# STM32G431xx register map
File version: 1.0
Registers are 32-bit, access not given, reset 0x0 unless marked. A register's access mark holds for its fields unless they carry their own. Offsets are from the block's base; [hi:lo] are bit positions; {n}, {i} and the like mark numbered series; 'fields as' and 'values as' point back to an identical list.

## EXTI
Base 0x40010400
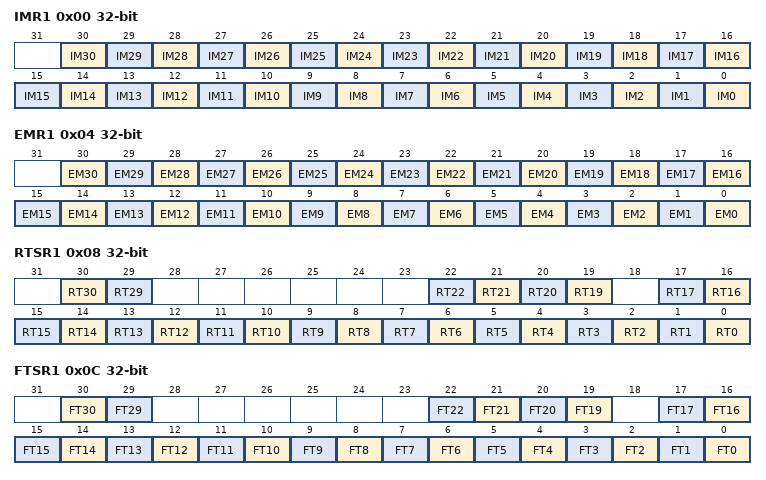
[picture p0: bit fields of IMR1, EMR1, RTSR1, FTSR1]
0x00 IMR1
  [n] IM{n} (n=0..30)
0x04 EMR1
  [n] EM{n} (n=0..30)
0x08 RTSR1
  [30] RT30, [29] RT29, [n] RT{n} (n=19..22), [n] RT{n} (n=0..17)
0x0C FTSR1
  [30] FT30, [29] FT29, [n] FT{n} (n=19..22), [n] FT{n} (n=0..17)
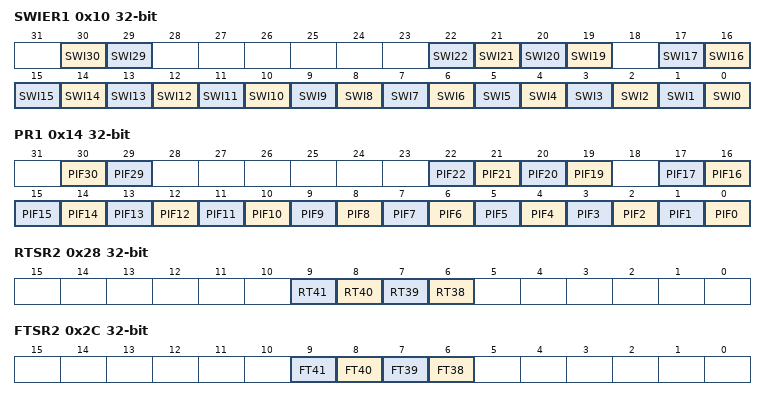
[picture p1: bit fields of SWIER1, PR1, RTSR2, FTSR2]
0x10 SWIER1
  [30] SWI30, [29] SWI29, [n] SWI{n} (n=19..22), [n] SWI{n} (n=0..17)
0x14 PR1
  [30] PIF30, [29] PIF29, [n] PIF{n} (n=19..22), [n] PIF{n} (n=0..17)
0x20 IMR2
  [n-32] IM{n} (n=36..41), [2] IM34, [9:0] IM
0x24 EMR2
  [n-32] EM{n} (n=36..41), [2] EM34, [9:0] EM
0x28 RTSR2
  [n-32] RT{n} (n=38..41)
0x2C FTSR2
  [n-32] FT{n} (n=38..41)
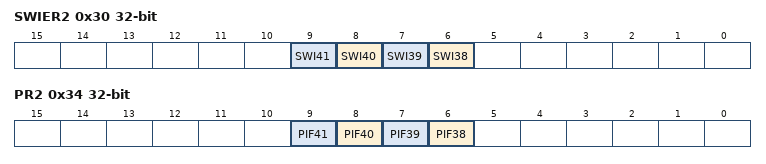
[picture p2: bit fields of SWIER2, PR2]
0x30 SWIER2
  [n-32] SWI{n} (n=38..41)
0x34 PR2
  [n-32] PIF{n} (n=38..41)

## SAI1
Base 0x40015400
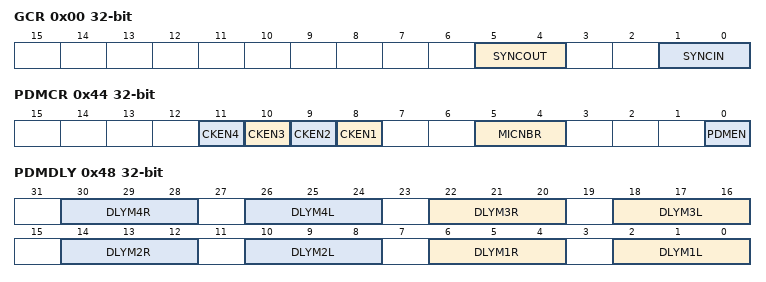
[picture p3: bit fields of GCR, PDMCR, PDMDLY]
0x00 GCR
  [5:4] SYNCOUT, [1:0] SYNCIN
0x04 CR1A
0x08 CR2A
0x10 FRCRA
0x1C SLOTRA
0x24 CR1B
0x28 CR2B
0x2C IMRA
0x30 FRCRB
0x3C SLOTRB
0x40 SRA
0x44 PDMCR
  [n+7] CKEN{n} (n=1..4), [5:4] MICNBR, [0] PDMEN
0x48 PDMDLY
  [8n-2:8n-4] DLYM{n}R (n=1..4), [8n-6:8n-8] DLYM{n}L (n=1..4)
0x4C IMRB
0x58 CLRFRA
0x60 SRB
0x74 DRA
0x78 CLRFRB
0x94 DRB

## DMA1
Base 0x40020000
Same registers: DMA2 0x40020400
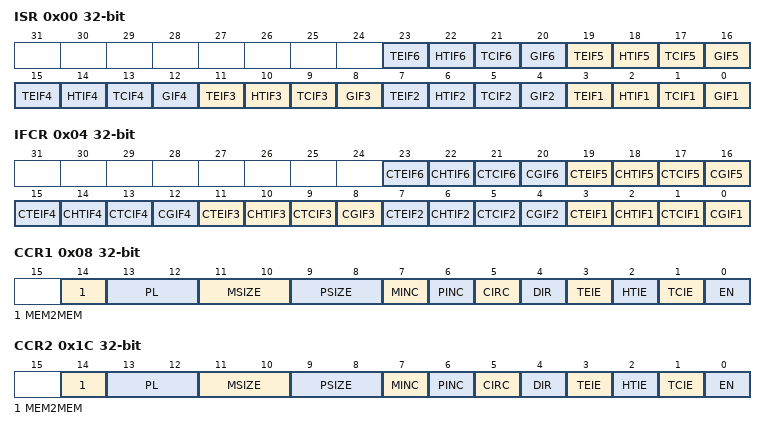
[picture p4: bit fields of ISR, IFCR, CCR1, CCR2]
0x00 ISR
  [4n-1] TEIF{n} (n=1..6), [4n-2] HTIF{n} (n=1..6), [4n-3] TCIF{n} (n=1..6), [4n-4] GIF{n} (n=1..6)
0x04 IFCR
  [4n-1] CTEIF{n} (n=1..6), [4n-2] CHTIF{n} (n=1..6), [4n-3] CTCIF{n} (n=1..6), [4n-4] CGIF{n} (n=1..6)
0x08 CCR1
  [14] MEM2MEM, [13:12] PL, [11:10] MSIZE, [9:8] PSIZE, [7] MINC, [6] PINC, [5] CIRC, [4] DIR, [3] TEIE, [2] HTIE, [1] TCIE, [0] EN
0x0C CNDTR1
  [15:0] NDT
{0x0+0x14*i} CPAR{i} (i=1..6)
  [31:0] PA
0x1C CCR2
  fields as CCR1
{0xC+0x14*i} CMAR{i} (i=1..6)
  [31:0] MA
0x20 CNDTR2
  [15:0] NDT
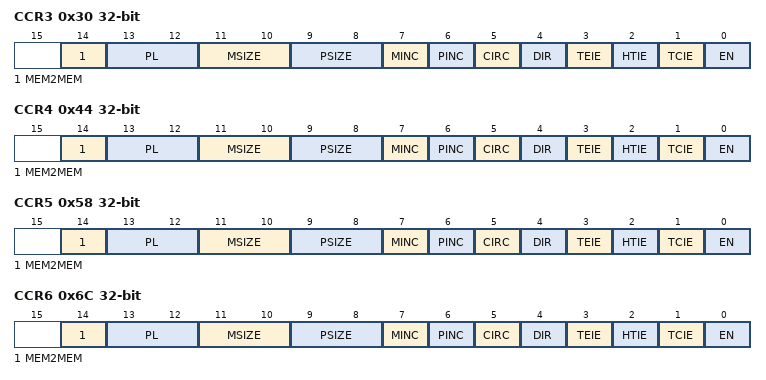
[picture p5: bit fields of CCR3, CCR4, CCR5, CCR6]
0x30 CCR3
  fields as CCR1
0x34 CNDTR3
  [15:0] NDT
0x44 CCR4
  fields as CCR1
0x48 CNDTR4
  [15:0] NDT
0x58 CCR5
  fields as CCR1
0x5C CNDTR5
  [15:0] NDT
0x6C CCR6
  fields as CCR1
0x70 CNDTR6
  [15:0] NDT

## DMAMUX1
Base 0x40020800
0x00 CCR0
0x04 CCR1
0x08 CCR2
0x0C CCR3
0x10 CCR4
0x14 CCR5
{0x8+4i} CCR{i} (i=6..9)
0x30 CCR0
0x34 CCR1
0x80 CCRs
0x100 CCR0
0x104 CCR1
0x108 CCR2
0x10C CCR3
0x140 CCRs

## CORDIC
Base 0x40020C00
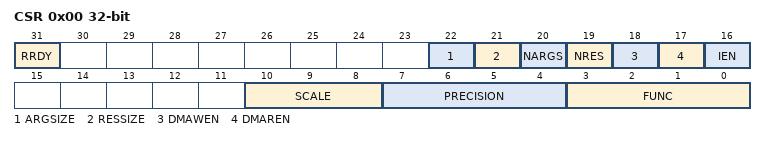
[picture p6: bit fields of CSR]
0x00 CSR
  [31] RRDY, [22] ARGSIZE, [21] RESSIZE, [20] NARGS, [19] NRES, [18] DMAWEN, [17] DMAREN, [16] IEN, [10:8] SCALE, [7:4] PRECISION, [3:0] FUNC
0x04 WDATA
  [31:0] ARG
0x08 RDATA
  [31:0] RES

## FMAC
Base 0x40021400
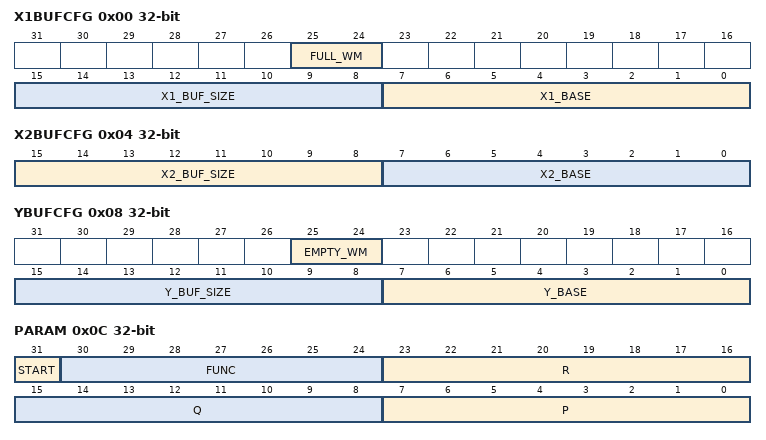
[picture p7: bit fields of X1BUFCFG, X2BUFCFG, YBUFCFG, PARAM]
0x00 X1BUFCFG
  [25:24] FULL_WM, [15:8] X1_BUF_SIZE, [7:0] X1_BASE
0x04 X2BUFCFG
  [15:8] X2_BUF_SIZE, [7:0] X2_BASE
0x08 YBUFCFG
  [25:24] EMPTY_WM, [15:8] Y_BUF_SIZE, [7:0] Y_BASE
0x0C PARAM
  [31] START, [30:24] FUNC, [23:16] R, [15:8] Q, [7:0] P
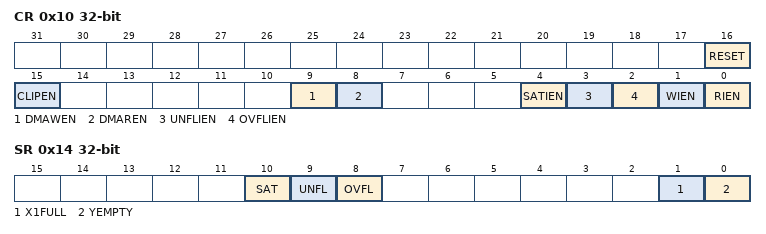
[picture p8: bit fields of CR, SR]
0x10 CR
  [16] RESET, [15] CLIPEN, [9] DMAWEN, [8] DMAREN, [4] SATIEN, [3] UNFLIEN, [2] OVFLIEN, [1] WIEN, [0] RIEN
0x14 SR
  [10] SAT, [9] UNFL, [8] OVFL, [1] X1FULL, [0] YEMPTY
0x18 WDATA
  [15:0] WDATA
0x1C RDATA
  [15:0] RDATA

## FLASH
Base 0x40022000
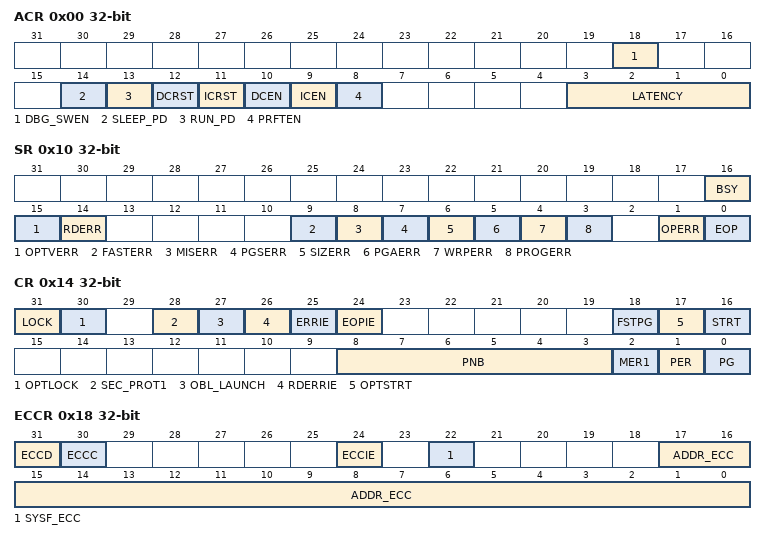
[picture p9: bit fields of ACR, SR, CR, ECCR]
0x00 ACR
  [18] DBG_SWEN, [14] SLEEP_PD, [13] RUN_PD, [12] DCRST, [11] ICRST, [10] DCEN, [9] ICEN, [8] PRFTEN, [3:0] LATENCY
0x04 PDKEYR
0x08 KEYR
0x0C OPTKEYR
0x10 SR
  [16] BSY, [15] OPTVERR, [14] RDERR, [9] FASTERR, [8] MISERR, [7] PGSERR, [6] SIZERR, [5] PGAERR, [4] WRPERR, [3] PROGERR, [1] OPERR, [0] EOP
0x14 CR
  [31] LOCK, [30] OPTLOCK, [28] SEC_PROT1, [27] OBL_LAUNCH, [26] RDERRIE, [25] ERRIE, [24] EOPIE, [18] FSTPG, [17] OPTSTRT, [16] STRT, [8:3] PNB, [2] MER1, [1] PER, [0] PG
0x18 ECCR
  [31] ECCD, [30] ECCC, [24] ECCIE, [22] SYSF_ECC, [17:0] ADDR_ECC
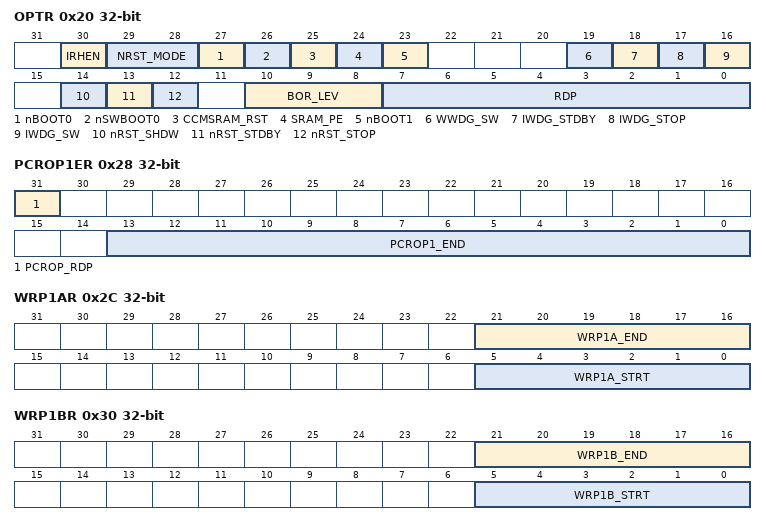
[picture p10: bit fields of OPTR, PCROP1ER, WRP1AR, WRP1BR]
0x20 OPTR
  [30] IRHEN, [29:28] NRST_MODE, [27] nBOOT0, [26] nSWBOOT0, [25] CCMSRAM_RST, [24] SRAM_PE, [23] nBOOT1, [19] WWDG_SW, [18] IWDG_STDBY, [17] IWDG_STOP, [16] IWDG_SW, [14] nRST_SHDW, [13] nRST_STDBY, [12] nRST_STOP, [10:8] BOR_LEV, [7:0] RDP
0x24 PCROP1SR
  [13:0] PCROP1_STRT
0x28 PCROP1ER
  [31] PCROP_RDP, [13:0] PCROP1_END
0x2C WRP1AR
  [21:16] WRP1A_END, [5:0] WRP1A_STRT
0x30 WRP1BR
  [21:16] WRP1B_END, [5:0] WRP1B_STRT
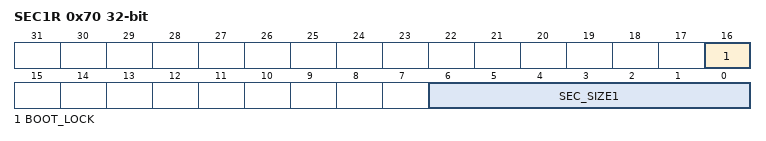
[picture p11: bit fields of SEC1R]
0x70 SEC1R
  [16] BOOT_LOCK, [6:0] SEC_SIZE1
